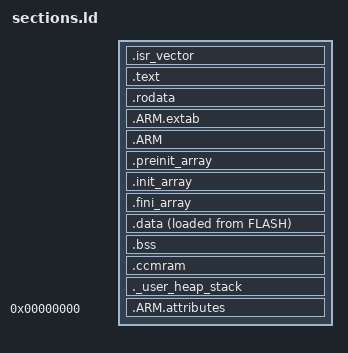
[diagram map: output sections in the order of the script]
/*
 * Common output sections for the bootloader and both application slots.
 * The including script defines the FLASH / RAM / CCMRAM memory regions and
 * _Min_Heap_Size / _Min_Stack_Size.
 */
ENTRY(Reset_Handler)

_estack = ORIGIN(RAM) + LENGTH(RAM);

SECTIONS
{
  .isr_vector :
  {
    . = ALIGN(4);
    KEEP(*(.isr_vector))
    . = ALIGN(4);
  } >FLASH

  .text :
  {
    . = ALIGN(4);
    *(.text)
    *(.text*)
    *(.glue_7)
    *(.glue_7t)
    *(.eh_frame)
    KEEP (*(.init))
    KEEP (*(.fini))
    . = ALIGN(4);
    _etext = .;
  } >FLASH

  .rodata :
  {
    . = ALIGN(4);
    *(.rodata)
    *(.rodata*)
    . = ALIGN(4);
  } >FLASH

  .ARM.extab (READONLY) : { *(.ARM.extab* .gnu.linkonce.armextab.*) } >FLASH
  .ARM (READONLY) :
  {
    __exidx_start = .;
    *(.ARM.exidx*)
    __exidx_end = .;
  } >FLASH

  .preinit_array (READONLY) :
  {
    PROVIDE_HIDDEN (__preinit_array_start = .);
    KEEP (*(.preinit_array*))
    PROVIDE_HIDDEN (__preinit_array_end = .);
  } >FLASH
  .init_array (READONLY) :
  {
    PROVIDE_HIDDEN (__init_array_start = .);
    KEEP (*(SORT(.init_array.*)))
    KEEP (*(.init_array*))
    PROVIDE_HIDDEN (__init_array_end = .);
  } >FLASH
  .fini_array (READONLY) :
  {
    PROVIDE_HIDDEN (__fini_array_start = .);
    KEEP (*(SORT(.fini_array.*)))
    KEEP (*(.fini_array*))
    PROVIDE_HIDDEN (__fini_array_end = .);
  } >FLASH

  _sidata = LOADADDR(.data);

  .data :
  {
    . = ALIGN(4);
    _sdata = .;
    *(.data)
    *(.data*)
    *(.RamFunc)
    *(.RamFunc*)
    . = ALIGN(4);
    _edata = .;
  } >RAM AT> FLASH

  /* Marks the end of the flash image; prepare-firmware.py relies on objcopy -O binary */
  _image_end = LOADADDR(.data) + SIZEOF(.data);

  .bss :
  {
    . = ALIGN(4);
    _sbss = .;
    __bss_start__ = _sbss;
    *(.bss)
    *(.bss*)
    *(COMMON)
    . = ALIGN(4);
    _ebss = .;
    __bss_end__ = _ebss;
  } >RAM

  /* CCM RAM (64 KB, CPU-only, not DMA-capable): FreeRTOS heap and task stacks.
   * Not initialised by the startup code, so only NOLOAD data may live here. */
  .ccmram (NOLOAD) :
  {
    . = ALIGN(8);
    *(.ccmram)
    *(.ccmram*)
    . = ALIGN(8);
  } >CCMRAM

  ._user_heap_stack :
  {
    . = ALIGN(8);
    PROVIDE ( end = . );
    PROVIDE ( _end = . );
    . = . + _Min_Heap_Size;
    . = . + _Min_Stack_Size;
    . = ALIGN(8);
  } >RAM

  /DISCARD/ :
  {
    libc.a ( * )
    libm.a ( * )
    libgcc.a ( * )
  }

  .ARM.attributes 0 : { *(.ARM.attributes) }
}
